# LAN9255ZMX019 register map
Vendor: Microchip
Registers are 32-bit, read-write, reset 0x0 unless marked. A register's access mark holds for its fields unless they carry their own. Addresses are absolute, and some are shared; only a register's first bit layout is shown; [hi:lo] are bit positions; {n}, {i} and the like mark numbered series; 'fields as' and 'values as' point back to an identical list.

## SystemControl
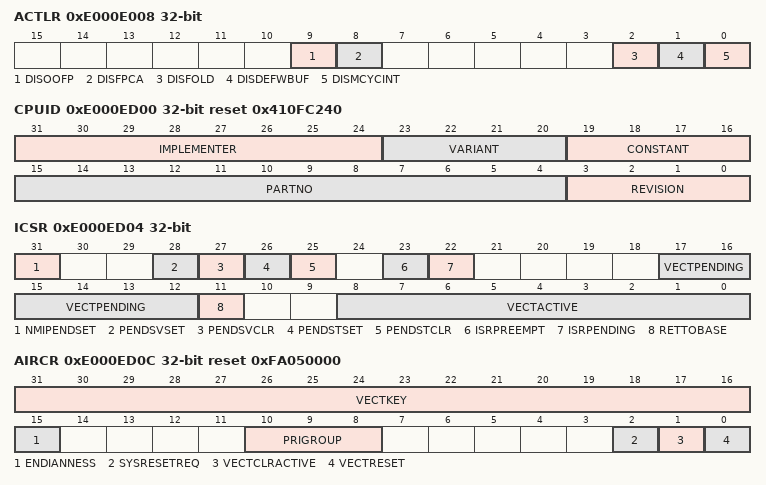
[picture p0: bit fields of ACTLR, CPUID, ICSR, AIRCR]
0xE000E008 ACTLR reset not defined
  [9] DISOOFP — Disable out-of-order FP instructions
  [8] DISFPCA — Disable automatic update of CONTROL.FPCA
  [2] DISFOLD — Disable IT folding
  [1] DISDEFWBUF — Disable wruite buffer use during default memory map accesses
  [0] DISMCYCINT — Disable interruption of LDM/STM instructions
0xE000ED00 CPUID ro reset 0x410FC240
  [31:24] IMPLEMENTER — Implementer code, 0x41=ARM
  [23:20] VARIANT — Variant number
  [19:16] CONSTANT
  [15:4] PARTNO — Process Part Number, 0xC24=Cortex-M4
  [3:0] REVISION — Processor revision number
0xE000ED04 ICSR
  [31] NMIPENDSET — NMI set-pending bit
    0=Write: no effect; read: NMI exception is not pending; 1=Write: changes NMI exception state to pending; read: NMI exception is pending
  [28] PENDSVSET — PendSV set-pending bit
    0=Write: no effect; read: PendSV exception is not pending; 1=Write: changes PendSV exception state to pending; read: PendSV exception is pending
  [27] PENDSVCLR — PendSV clear-pending bit
    0=No effect; 1=Removes the pending state from the PendSV exception
  [26] PENDSTSET — SysTick set-pending bit
    0=Write: no effect; read: SysTick exception is not pending; 1=Write: changes SysTick exception state to pending; read: SysTick exception is pending
  [25] PENDSTCLR — SysTick clear-pending bit
    0=No effect; 1=Removes the pending state from the SysTick exception
  [23] ISRPREEMPT — Debug only
  [22] ISRPENDING — Interrupt pending flag
  [17:12] VECTPENDING — Exception number of the highest priority pending enabled exception
  [11] RETTOBASE — No preempted active exceptions to execute
  [8:0] VECTACTIVE — Active exception number
0xE000ED08 VTOR
  [31:7] TBLOFF — Vector table base offset
0xE000ED0C AIRCR reset 0xFA050000
  [31:16] VECTKEY — Register key
  [15] ENDIANNESS — Data endianness, 0=little, 1=big
    0=Little-endian; 1=Big-endian
  [10:8] PRIGROUP — Interrupt priority grouping
  [2] SYSRESETREQ — System Reset Request
    0=No system reset request; 1=Asserts a signal to the outer system that requests a reset
  [1] VECTCLRACTIVE — Must write 0
  [0] VECTRESET — Must write 0
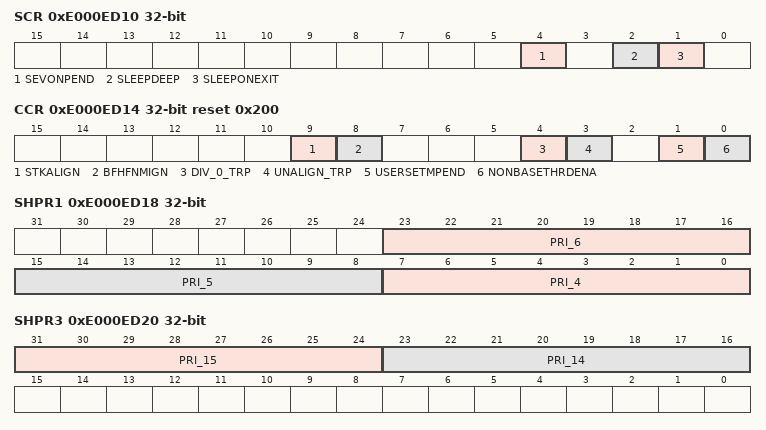
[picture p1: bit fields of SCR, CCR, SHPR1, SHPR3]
0xE000ED10 SCR
  [4] SEVONPEND — Send Event on Pending bit
    0=Only enabled interrupts or events can wakeup the processor, disabled interrupts are excluded; 1=Enabled events and all interrupts, including disabled interrupts, can wakeup the processor
  [2] SLEEPDEEP — Deep Sleep used as low power mode
    0=Sleep; 1=Deep sleep
  [1] SLEEPONEXIT — Sleep-on-exit on handler return
    0=Do not sleep when returning to Thread mode; 1=Enter sleep, or deep sleep, on return from an ISR
0xE000ED14 CCR reset 0x200
  [9] STKALIGN — Indicates stack alignment on exception entry
    0=4-byte aligned; 1=8-byte aligned
  [8] BFHFNMIGN — Ignore LDM/STM BusFault for -1/-2 priority handlers
  [4] DIV_0_TRP — Enables divide by 0 trap
  [3] UNALIGN_TRP — Enables unaligned access traps
    0=Do not trap unaligned halfword and word accesses; 1=Trap unaligned halfword and word accesses
  [1] USERSETMPEND — Enables unprivileged software access to STIR register
  [0] NONBASETHRDENA — Indicates how processor enters Thread mode
0xE000ED18 SHPR1 reset not defined
  [23:16] PRI_6 — Priority of system handler 6, UsageFault
  [15:8] PRI_5 — Priority of system handler 5, BusFault
  [7:0] PRI_4 — Priority of system handler 4, MemManage
0xE000ED1C SHPR2
  [31:24] PRI_11 — Priority of system handler 11, SVCall
0xE000ED20 SHPR3
  [31:24] PRI_15 — Priority of system handler 15, SysTick exception
  [23:16] PRI_14 — Priority of system handler 14, PendSV
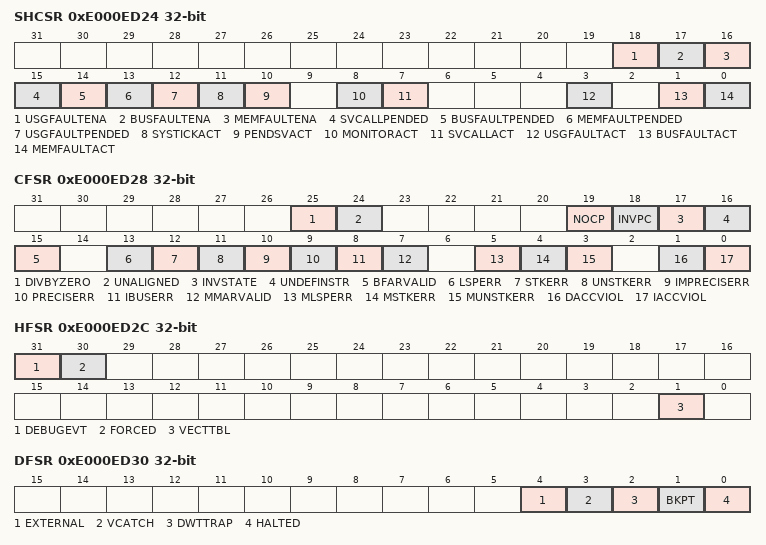
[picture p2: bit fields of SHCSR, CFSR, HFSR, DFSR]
0xE000ED24 SHCSR reset not defined
  [18] USGFAULTENA — UsageFault enable bit
  [17] BUSFAULTENA — BusFault enable bit
  [16] MEMFAULTENA — MemManage enable bit
  [15] SVCALLPENDED — SVCall pending bit
  [14] BUSFAULTPENDED — BusFault exception pending bit
  [13] MEMFAULTPENDED — MemManage exception pending bit
  [12] USGFAULTPENDED — UsageFault exception pending bit
  [11] SYSTICKACT — SysTick exception active bit
  [10] PENDSVACT — PendSV exception active bit
  [8] MONITORACT — DebugMonitor exception active bit
  [7] SVCALLACT — SVCall active bit
  [3] USGFAULTACT — UsageFault exception active bit
  [1] BUSFAULTACT — BusFault exception active bit
  [0] MEMFAULTACT — MemManage exception active bit
0xE000ED28 CFSR reset not defined
  [25] DIVBYZERO — Divide by zero UsageFault
  [24] UNALIGNED — Unaligned access UsageFault
  [19] NOCP — No coprocessor UsageFault
  [18] INVPC — Invalid PC load UsageFault
  [17] INVSTATE — Invalid state UsageFault
  [16] UNDEFINSTR — Undefined instruction UsageFault
  [15] BFARVALID — BusFault Address Register valid
  [13] LSPERR — BusFault occured during FP lazy state preservation
  [12] STKERR — BusFault on stacking for exception entry
  [11] UNSTKERR — BusFault on unstacking for exception return
  [10] IMPRECISERR — Imprecise data bus error
  [9] PRECISERR — Precise data bus error
  [8] IBUSERR — Instruction bus error
  [7] MMARVALID — MemManage Fault Address Register valid
  [5] MLSPERR — MemManager Fault occured during FP lazy state preservation
  [4] MSTKERR — MemManage Fault on stacking for exception entry
  [3] MUNSTKERR — MemManage Fault on unstacking for exception return
  [1] DACCVIOL — Data access violation
  [0] IACCVIOL — Instruction access violation
0xE000ED2C HFSR reset not defined
  [31] DEBUGEVT — Debug: always write 0
  [30] FORCED — Forced Hard Fault
  [1] VECTTBL — BusFault on a Vector Table read during exception processing
0xE000ED30 DFSR reset not defined
  [4] EXTERNAL, [3] VCATCH, [2] DWTTRAP, [1] BKPT, [0] HALTED
0xE000ED34 MMFAR reset not defined
  [31:0] ADDRESS — Address that generated the MemManage fault
0xE000ED38 BFAR reset not defined
  [31:0] ADDRESS — Address that generated the BusFault
0xE000ED3C AFSR reset not defined
  [31:0] IMPDEF — AUXFAULT input signals
0xE000ED40 PFR0 reset not defined
0xE000ED44 PFR1 reset not defined
0xE000ED48 DFR ro reset not defined
0xE000ED4C ADR ro reset not defined
{0xE000ED50+4i} MMFR{i} ro reset not defined (i=0..3)
{0xE000ED60+4i} ISAR{i} ro reset not defined (i=0..4)
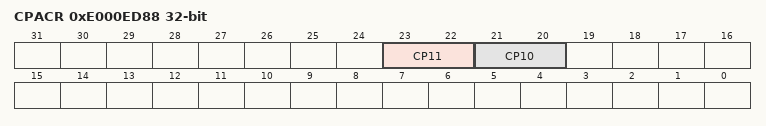
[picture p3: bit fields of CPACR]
0xE000ED88 CPACR reset not defined
  [23:22] CP11 — Access privileges for coprocessor 11
    0=DENIED (Access denied); 1=PRIV (Privileged access only); 3=FULL (Full access)
  [21:20] CP10 — Access privileges for coprocessor 10
    values as CP11
